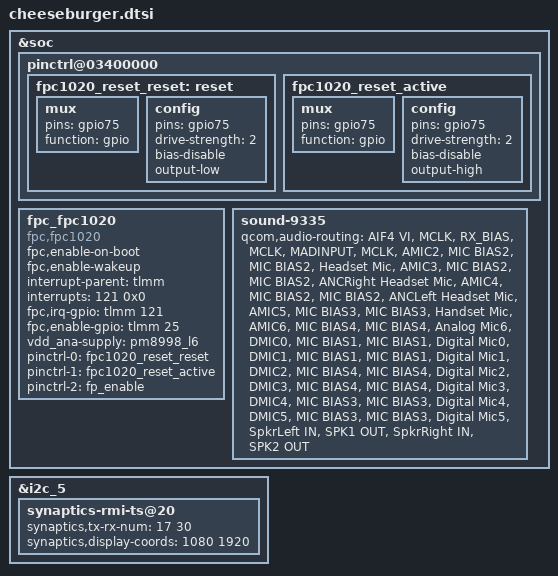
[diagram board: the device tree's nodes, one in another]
/* Copyright (c) 2016-2017, The Linux Foundation. All rights reserved.
 *
 * This program is free software; you can redistribute it and/or modify
 * it under the terms of the GNU General Public License version 2 and
 * only version 2 as published by the Free Software Foundation.
 *
 * This program is distributed in the hope that it will be useful,
 * but WITHOUT ANY WARRANTY; without even the implied warranty of
 * MERCHANTABILITY or FITNESS FOR A PARTICULAR PURPOSE.  See the
 * GNU General Public License for more details.
 */

#include "msm8998-oneplus-common.dtsi"

/* I/O */
&soc {
	pinctrl@03400000 {
		/* Fingerprint */
		/* GPIO_40 : FP_RESET_N */
		fpc1020_reset_reset: reset {
			mux {
				pins = "gpio75";
				function = "gpio";
			};

			config {
				pins = "gpio75";
				drive-strength = <2>;
				bias-disable;
				output-low;
			};
		};

		/* GPIO_40 : FP_RESET_N, state device active */
		fpc1020_reset_active: fpc1020_reset_active {
			mux {
				pins = "gpio75";
				function = "gpio";
			};

			config {
				pins = "gpio75";
				drive-strength = <2>;
				bias-disable;
				output-high;
			};
		};
	};

	fpc_fpc1020 {
		compatible = "fpc,fpc1020";
		fpc,enable-on-boot;
		fpc,enable-wakeup;
		interrupt-parent = <&tlmm>;
		interrupts = <121 0x0>;
		fpc,irq-gpio    = <&tlmm 121 0x0>;
		fpc,enable-gpio = <&tlmm 25 0x0>;
		vdd_ana-supply  = <&pm8998_l6>;

		pinctrl-names = "fpc1020_reset_reset",
				"fpc1020_reset_active",
				"fp_enable";

		pinctrl-0 = <&fpc1020_reset_reset>;
		pinctrl-1 = <&fpc1020_reset_active>;
		pinctrl-2 = <&fp_enable>;
	};
};

/* Display */
&i2c_5 {
	synaptics-rmi-ts@20 {
		status = "ok";
		synaptics,tx-rx-num = <17 30>;
		synaptics,display-coords = <1080 1920>;
	};
};

/* Audio */
&soc {
	sound-9335 {
		status = "ok";
		qcom,audio-routing =
			"AIF4 VI", "MCLK",
			"RX_BIAS", "MCLK",
			"MADINPUT", "MCLK",
			"AMIC2", "MIC BIAS2",
			"MIC BIAS2", "Headset Mic",
			"AMIC3", "MIC BIAS2",
			"MIC BIAS2", "ANCRight Headset Mic",
			"AMIC4", "MIC BIAS2",
			"MIC BIAS2", "ANCLeft Headset Mic",
			"AMIC5", "MIC BIAS3",
			"MIC BIAS3", "Handset Mic",
			"AMIC6", "MIC BIAS4",
			"MIC BIAS4", "Analog Mic6",
			"DMIC0", "MIC BIAS1",
			"MIC BIAS1", "Digital Mic0",
			"DMIC1", "MIC BIAS1",
			"MIC BIAS1", "Digital Mic1",
			"DMIC2", "MIC BIAS4",
			"MIC BIAS4", "Digital Mic2",
			"DMIC3", "MIC BIAS4",
			"MIC BIAS4", "Digital Mic3",
			"DMIC4", "MIC BIAS3",
			"MIC BIAS3", "Digital Mic4",
			"DMIC5", "MIC BIAS3",
			"MIC BIAS3", "Digital Mic5",
			"SpkrLeft IN", "SPK1 OUT",
			"SpkrRight IN", "SPK2 OUT";
	};
};
